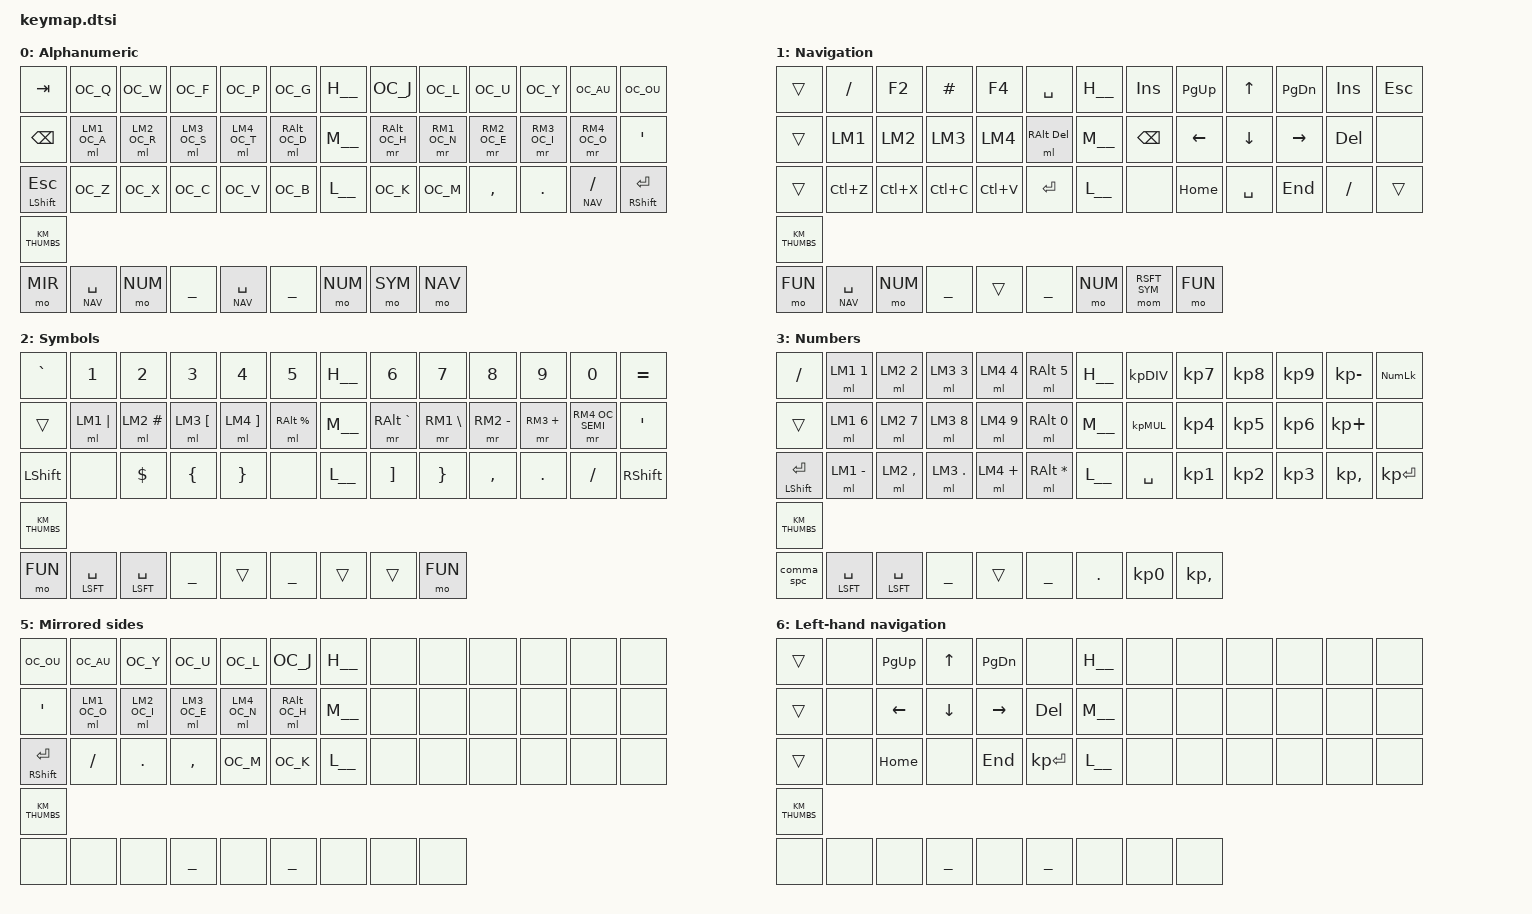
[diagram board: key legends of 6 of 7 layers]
/*
 * Copyright (c) 2020 The ZMK Contributors
 *
 * SPDX-License-Identifier: MIT
 */

#include <behaviors.dtsi>
#include <dt-bindings/zmk/keys.h>
#include <dt-bindings/zmk/bt.h>
#include <dt-bindings/zmk/outputs.h>

#include "./lib/keys_os_colemak.h"
#include "./base.h"

// Layers
#define DEF 0
#define NAV 1
#define SYM 2
#define NUM 3
#define FUN 4
#define MIR 5
#define NAL 6

#define LAYERS_ALL DEF NAV SYM NUM FUN MIR NAL
#define LAYERS_ALPHANUM DEF SYM NUM MIR

#include "./behaviors.dtsi"
#include "./combos.dtsi"
#include "./macros.dtsi"

/ {
	//conditional_layers {
	//	compatible = "zmk,conditional-layers";
	//	tri_layer {
	//		if-layers = <NAV SYM>;
	//		then-layer = <NUM>;
	//	};
	//};

	keymap {
		compatible = "zmk,keymap";

		// Colemak on OS side
		// |     |  Q  |  W  |  F  |  P  |  G  |   |  J  |  L  |  U  |  Y  |  Ä  |  Ö  |
		// |     |  A  |  R  |  S  |  T  |  D  |   |  H  |  N  |  E  |  I  |  O  |  '  |
		// |     |  Z  |  X  |  C  |  V  |  B  |   |  K  |  M  |  ,  |  .  |  /  |     |
		alpha_layer {
			display-name = "Alphanumeric";
			bindings = <
&kp TAB        &kp OC_Q      &kp OC_W      &kp OC_F     &kp OC_P     &kp OC_G      __H__ &kp OC_J      &kp OC_L      &kp OC_U     &kp OC_Y     &kp OC_AU    &kp OC_OU
&kp BSPC       &ml LM1 OC_A  &ml LM2 OC_R  &ml LM3 OC_S &ml LM4 OC_T &ml RALT OC_D __M__ &mr RALT OC_H &mr RM1 OC_N  &mr RM2 OC_E &mr RM3 OC_I &mr RM4 OC_O &kp SQT
&mt LSHFT ESC  &kp OC_Z      &kp OC_X      &kp OC_C     &kp OC_V     &kp OC_B      __L__ &kp OC_K      &kp OC_M      &kp COMMA    &kp DOT      &lt NAV FSLH &mt RSHFT RET
KM_THUMBS(
	&mo MIR, &lt NAV SPACE, &mo NUM, ___ &lt NAV SPACE, ___ &mo NUM, &mo SYM, &mo NAV
)
			>;
		};

		navigation_layer {
			display-name = "Navigation";
			bindings = <
&trans   &kp FSLH      &kp F2     &kp HASH   &kp F4     &kp SPACE      __H__ &kp INS       &kp PG_UP     &kp UP     &kp PG_DN  &kp INS   &kp ESC
&trans   &kp LM1       &kp LM2    &kp LM3    &kp LM4    &ml RALT DEL   __M__ &kp BSPC      &kp LEFT      &kp DOWN   &kp RIGHT  &kp DEL   &none
&trans   &kp LC(Z)     &kp LC(X)  &kp LC(C)  &kp LC(V)  &kp RET        __L__ &none         &kp HOME      &kp SPACE  &kp END    &kp FSLH  &trans
KM_THUMBS(
	&mo FUN, &lt NAV SPACE, &mo NUM, ___ &trans, ___ &mo NUM, &mom RSFT SYM, &mo FUN
)
			>;
		};

//   ~     !     @     #     $     %         ^     &     *     (     )     +
// | `   | 1   | 2   | 3   | 4   | 5   |   | 6   | 7   | 8   | 9   | 0   | =   |
// |     | |   | #   | [   | ]   | %   |   | `   | \   | -   | +   | ;   | '   |
// |     |     | $   | {   | }   |     |   |     |     | ,   | .   | /   |     |
		symbol_layer {
			display-name = "Symbols";
			bindings = <
&kp GRAVE  &kp N1       &kp N2       &kp N3       &kp N4       &kp N5         __H__ &kp N6         &kp N7        &kp N8        &kp N9        &kp N0          &kp EQUAL
&trans     &ml LM1 PIPE &ml LM2 HASH &ml LM3 LBKT &ml LM4 RBKT &ml RALT PRCNT __M__ &mr RALT GRAVE &mr RM1 BSLH  &mr RM2 MINUS &mr RM3 PLUS  &mr RM4 OC_SEMI &kp SQT
&kp LSHFT  &none        &kp DLLR     &kp LBRC     &kp RBRC     &none          __L__ &kp RBKT       &kp RBRC      &kp COMMA     &kp DOT       &kp FSLH        &kp RSHFT
KM_THUMBS(
	&mo FUN, &mt LSFT SPACE, &mt LSFT SPACE, ___ &trans, ___ &trans, &trans, &mo FUN
)
			>;
		};

// | /   | 1   | 2   | 3   | 4   | 5   |
// |     | 6   | 7   | 8   | 9   | 0   |
// |     | -   | ,   | .   | +   | *   |
//		left_symbol_layer {
//			display-name = "Left-hand symbols";
//			bindings = <
//&kp FSLH      &ml LM1 N1     &ml LM2 N2     &ml LM3 N3   &ml LM4 N4   &ml RALT N5   __H__ &trans &trans &trans &trans &trans &trans
//&trans        &ml LM1 N6     &ml LM2 N7     &ml LM3 N8   &ml LM4 N9   &ml RALT N0   __M__ &trans &trans &trans &trans &trans &trans
//&mt LSHFT RET &ml LM1 MINUS  &ml LM2 COMMA  &ml LM3 DOT  &ml LM4 PLUS &ml RALT STAR __L__ &trans &trans &trans &trans &trans &trans
//&comma_spc    &mt LSFT SPACE &mt LSFT SPACE                                         ___ &trans &trans &trans
//			>;
//		};

// | /   | 1   | 2   | 3   | 4   | 5   |   | /   | 7   | 8   | 9   | -   | NLK |
// |     | 6   | 7   | 8   | 9   | 0   |   | *   | 4   | 5   | 6   | +   |     |
// | RET | -   | ,   | .   | +   | *   |   |     | 1   | 2   | 3   | .   | RET |
		number_layer {
			display-name = "Numbers";
			bindings = <
&kp FSLH      &ml LM1 N1     &ml LM2 N2     &ml LM3 N3   &ml LM4 N4   &ml RALT N5   __H__ &kp KP_DIV  &kp KP_N7  &kp KP_N8  &kp KP_N9  &kp KP_MINUS  &kp KP_NUMLOCK
&trans        &ml LM1 N6     &ml LM2 N7     &ml LM3 N8   &ml LM4 N9   &ml RALT N0   __M__ &kp KP_MUL  &kp KP_N4  &kp KP_N5  &kp KP_N6  &kp KP_PLUS   &none
&mt LSHFT RET &ml LM1 MINUS  &ml LM2 COMMA  &ml LM3 DOT  &ml LM4 PLUS &ml RALT STAR __L__ &kp SPACE   &kp KP_N1  &kp KP_N2  &kp KP_N3  &kp KP_COMMA  &kp KP_ENTER
KM_THUMBS(
	&comma_spc, &mt LSFT SPACE, &mt LSFT SPACE, ___ &trans, ___ &kp DOT, &kp KP_N0, &kp KP_COMMA
)
			>;
		};

		function_layer {
			display-name = "Function";
			bindings = <
&out OUT_USB &kp SYSREQ   &none        &unstick     &studio_unlock &bootloader  __H__  &kp C_VOL_UP     &kp F1  &kp F2  &kp F3  &kp F4  &kp PRINTSCREEN
&kp CAPSLOCK &kp LM1      &kp LM2      &kp LM3      &kp LM4        &kp RALT     __M__  &kp C_VOL_DN     &kp F5  &kp F6  &kp F7  &kp F8  &kp PAUSE_BREAK
&out OUT_BLE &bt BT_SEL 0 &bt BT_SEL 1 &bt BT_SEL 2 &bt BT_SEL 3   &bt BT_CLR   __L__  &kp C_PLAY_PAUSE &kp F9  &kp F10 &kp F11 &kp F12 &kp SCROLLLOCK
KM_THUMBS(
	&none, &none, &none, ___ &none, ___ &none, &none, &none
)
			>;
		};

		mirror_layer {
			display-name = "Mirrored sides";
			bindings = <
&kp OC_OU     &kp OC_AU    &kp OC_Y     &kp OC_U     &kp OC_L     &kp OC_J      __H__ &none  &none  &none  &none  &none  &none
&kp SQT       &ml LM1 OC_O &ml LM2 OC_I &ml LM3 OC_E &ml LM4 OC_N &ml RALT OC_H __M__ &none  &none  &none  &none  &none  &none
&mt RSHFT RET &kp FSLH     &kp DOT      &kp COMMA    &kp OC_M     &kp OC_K      __L__ &none  &none  &none  &none  &none  &none
KM_THUMBS(
	&none, &none, &none, ___ &none, ___ &none, &none, &none
)
			>;
		};

		navigation_layer_left {
			display-name = "Left-hand navigation";
			bindings = <
&trans  &none      &kp PG_UP  &kp UP     &kp PG_DN  &none         __H__ &none  &none  &none  &none  &none  &none
&trans  &none      &kp LEFT   &kp DOWN   &kp RIGHT  &kp DEL       __M__ &none  &none  &none  &none  &none  &none
&trans  &none      &kp HOME   &none      &kp END    &kp KP_ENTER  __L__ &none  &none  &none  &none  &none  &none
KM_THUMBS(
	&none, &none, &none, ___ &none, ___ &none, &none, &none
)
			>;
		};

//		kicad_layer {
//			display-name = "KiCad";
//			bindings = <
//&trans   &kp LEFT   &kp N7  &kp N8  &kp N9  &kp RIGHT  ___ &none  &none  &none  &none  &none  &none
//&trans   &kp COMMA  &kp N4  &kp N5  &kp N6  &kp DOT    ___ &none  &none  &none  &none  &none  &none
//&trans   &kp N0     &kp N1  &kp N2  &kp N3  &kp RET    ___ &none  &none  &none  &none  &none  &none
//KM_THUMBS(
//	&none, &none, &none, ___ &none, ___ &none, &none, &none
//)
//			>;
//		};

////   ~     !     @     #     $     %
////         ^     &     *     (     )         ^     &     *     (     )
//// | `   | 1   | 2   | 3   | 4   | 5   |   | 6   | 7   | 8   | 9   | 0   | =   |
//// |     | 6   | 7   | 8   | 9   | 0   |   | \   | |   | -   | +   | ;   | '   |
//// |     |     | \   | $   | [   | {   |   | }   | ]   | ,   | .   | /   |     |
//		symbol_layer {
//			bindings = <
//&kp GRAVE   &kp N1         &kp N2     &kp N3     &kp N4     &kp N5      ___ &kp N6        &kp N7       &kp N8        &kp N9       &kp N0  &kp EQUAL
//&trans      &ml LM1 N6     &ml LM2 N7 &ml LM3 N8 &ml LM4 N9 &ml RALT N0 ___ &mr RALT BSLH &mr RM1 PIPE &mr RM2 MINUS &mr RM3 PLUS &mr RM4 OC_SEMI &kp SQT
//&trans      &none          &kp BSLH   &kp DLLR   &kp LBKT   &kp LBRC    ___ &kp RBRC      &kp RBKT     &kp COMMA     &kp DOT      &kp FSLH     &trans
//&comma_spc  &kt_spc LSFT 0 &kt_spc LSFT 0                               ___ &trans        &trans       &mo FUN
//			>;
//		};
//
////   ~     !     @     #     $     %
////         ^     &     *     (     )
//// | `   | 1   | 2   | 3   | 4   | 5   |   |     | |   | -   | +   | ;   | =   |
//// |     | 6   | 7   | 8   | 9   | 0   |   | \   | {   | (   | )   | }   | '   |
//// |     |     | [   | ]   |     |     |   |     | $   | ,   | .   | /   |     |
//		symbol_layer {
//			bindings = <
//&kp GRAVE   &kp N1         &kp N2     &kp N3     &kp N4     &kp N5      ___ &none         &kp PIPE     &kp MINUS    &kp PLUS     &kp OC_SEMI  &kp EQUAL
//&trans      &ml LM1 N6     &ml LM2 N7 &ml LM3 N8 &ml LM4 N9 &ml RALT N0 ___ &mr RALT BSLH &mr RM1 LBRC &mr RM2 LPAR &mr RM3 RPAR &mr RM4 RBRC &kp SQT
//&trans      &none          &kp LBKT   &kp RBKT   &none      &none       ___ &none         &kp DLLR     &kp COMMA    &kp DOT      &kp FSLH     &trans
//&comma_spc  &kt_spc LSFT 0 &kt_spc LSFT 0                               ___ &trans        &trans       &mo FUN
//			>;
//		};

////   ~     !     @     #     $     %
////         ^     &     *     (     )
//// |     | `   | 7   | 8   | 9   |     |   |     | |   | -   | +   | ;   | =   |
//// |     | ,   | 4   | 5   | 6   | 0   |   | \   | {   | (   | )   | }   | '   |
//// |     | [   | 1   | 2   | 3   | ]   |   |     | $   | ,   | .   | /   |     |
//		symbol_layer {
//			bindings = <
//&kp GRAVE   &none          &kp N7     &kp N8     &kp N9     &none       ___ &none         &kp PIPE     &kp MINUS    &kp PLUS     &kp OC_SEMI  &kp EQUAL
//&trans      &ml LM1 DOT    &ml LM2 N4 &ml LM3 N5 &ml LM4 N6 &ml RALT N0 ___ &mr RALT BSLH &mr RM1 LBRC &mr RM2 LPAR &mr RM3 RPAR &mr RM4 RBRC &kp SQT
//&trans      &kp LBKT       &kp N1     &kp N2     &kp N3     &kp RBKT    ___ &none         &kp DLLR     &kp COMMA    &kp DOT      &kp FSLH     &trans
//&comma_spc  &kt_spc LSFT 0 &kt_spc LSFT 0                               ___ &trans        &trans       &mo FUN
//			>;
//		};

////   ~     !     @     #     $     %         ^     &     *     (     )
//// | `   | !   | &   | $   | {   | %   |   | ^   | }   | -   | +   | ;   | =   |
//// |     | 1   | 2   | 3   | 4   | 5   |   | 6   | 7   | 8   | 9   | 0   | '   |
//// |     | |   | \   | #   | (   | [   |   | ]   | )   | ,   | .   | /   |     |
//		symbol_layer {
//			bindings = <
//&kp GRAVE   &kp EXCL       &kp AMPS   &kp DLLR   &kp LBRC   &kp PRCNT   ___ &kp CARET   &kp RBRC   &kp MINUS  &kp PLUS   &kp OC_SEMI &kp EQUAL
//&trans      &ml LM1 N1     &ml LM2 N2 &ml LM3 N3 &ml LM4 N4 &ml RALT N5 ___ &mr RALT N6 &mr RM1 N7 &mr RM2 N8 &mr RM3 N9 &mr RM4 N0  &kp SQT
//&trans      &kp PIPE       &kp BSLH   &kp HASH   &kp LPAR   &kp LBKT    ___ &kp RBKT    &kp RPAR   &kp COMMA  &kp DOT    &kp FSLH    &trans
//&comma_spc  &kt_spc LSFT 0 &kt_spc LSFT 0                               ___ &trans      &trans     &mo FUN
//			>;
//		};

////   ~     !     @     #     $     %         ^     &     *     (     )
//// | `   | !   | @   | #   | $   | %   |   | ^   | &   | -   | +   | ;   | =   |
//// |     | 1   | 2   | 3   | 4   | 5   |   | 6   | 7   | 8   | 9   | 0   | '   |
//// |     | [   | ]   | {   | }   |     |   | \   | |   | ,   | .   | /   |     |
//		symbol_layer {
//			bindings = <
//&kp GRAVE   &kp EXCL       &kp AMPS   &kp DLLR   &kp LBRC   &kp PRCNT   ___ &kp CARET   &kp RBRC   &kp MINUS  &kp PLUS   &kp OC_SEMI &kp EQUAL
//&trans      &ml LM1 N1     &ml LM2 N2 &ml LM3 N3 &ml LM4 N4 &ml RALT N5 ___ &mr RALT N6 &mr RM1 N7 &mr RM2 N8 &mr RM3 N9 &mr RM4 N0  &kp SQT
//&trans      &kp PIPE       &kp BSLH   &kp HASH   &kp LPAR   &kp LBKT    ___ &kp RBKT    &kp RPAR   &kp COMMA  &kp DOT    &kp FSLH    &trans
//&comma_spc  &kt_spc LSFT 0 &kt_spc LSFT 0                               ___ &trans      &trans     &mo FUN
//			>;
//		};
	};
};
